# Template register map
Vendor: VendorName Co.Ltd; Series: SeriesName; File version: 1.2
CPU: CM7 r0p1, little endian, MPU, FPU, 4 interrupt priority bits
Registers are 32-bit, read-write, no defined reset value unless marked. A register's access mark holds for its fields unless they carry their own. Offsets are from the block's base; [hi:lo] are bit positions; {n}, {i} and the like mark numbered series.

## SMPU — System Memory Protection Unit
Base 0x400B3000
{0x0+4i} SEDMA1[{i}] (i=0..7) — Grouping of EDMA1 Start Addr
  [31:5] SEDMA1 — SMPU SEDMA1[26:0] bit: protection start address set of EDMA1 region n corrsponding MPU
{0x80+4i} SEDMA2[{i}] (i=0..7) — Grouping of EDMA2 Start Addr
  [31:5] SEDMA2 — SMPU SEDMA2[26:0] bit: protection start address set of EDMA2 region n corrsponding MPU
{0x100+4i} EEDMA1[{i}] (i=0..7) — Grouping of EDMA1 End Addr
  [31:5] EEDMA1 — SMPU EEDMA1[26:0] bit: protection end address set of EDMA1 region n corrsponding MPU
{0x180+4i} EEDMA2[{i}] (i=0..7) — Grouping of EDMA2 End Addr
  [31:5] EEDMA2 — SMPU EEDMA2[26:0] bit: protection end address set of EDMA2 region n corrsponding MPU
{0x200+4i} SAES[{i}] (i=0..3) — Grouping of AES-HASH Start Addr
  [31:5] SAES — SMPU SAES[26:0] bit: protection start address set of HASH-AES region n corrsponding MPU
{0x210+4i} SEMATH[{i}] (i=0..3) — Grouping of EMATH Start Addr
  [31:5] SEMATH — SMPU SEMATH[26:0] bit: protection start address set of EMATH region n corrsponding MPU
{0x220+4i} EAES[{i}] (i=0..3) — Grouping of AES-HASH End Addr
  [31:5] EAES — SMPU EAES[26:0] bit: protection end address set of HASH-AES region n corrsponding MPU
{0x230+4i} EEMATH[{i}] (i=0..3) — Grouping of EMATH End Addr
  [31:5] EEMATH — SMPU EEMATH[26:0] bit: protection end address set of EMATH region n corrsponding MPU
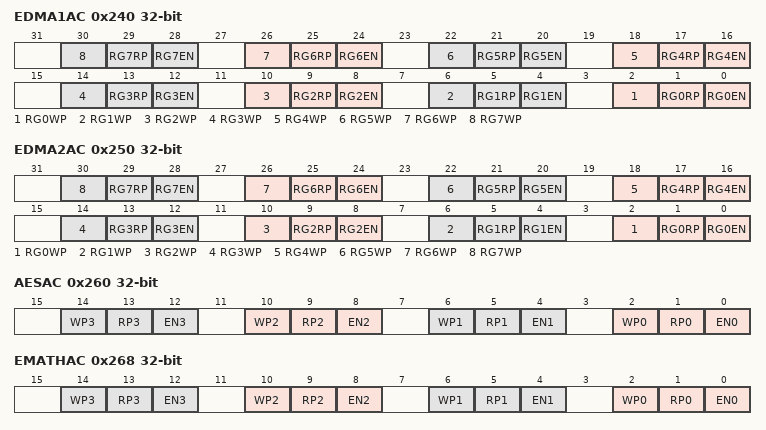
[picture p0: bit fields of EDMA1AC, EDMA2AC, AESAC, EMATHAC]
0x240 EDMA1AC — SMPU EDMA1 read-write access permission control register
  [4n+2] RG{n}WP (n=0..7) — SMPU RG{n}WP bit: region {n} EDMA1 MPU write protection
  [4n+1] RG{n}RP (n=0..7) — SMPU RG{n}RP bit: region {n} EDMA1 MPU read protection
  [4n] RG{n}EN (n=0..7) — SMPU RG{n}EN bit: region {n} EDMA1 MPU protection enable
0x250 EDMA2AC — SMPU EDMA2 read-write access permission control register
  [4n+2] RG{n}WP (n=0..7) — SMPU RG{n}WP bit: region {n} EDMA2 MPU write protection
  [4n+1] RG{n}RP (n=0..7) — SMPU RG{n}RP bit: region {n} EDMA2 MPU read protection
  [4n] RG{n}EN (n=0..7) — SMPU RG{n}EN bit: region {n} EDMA2 MPU protection enable
0x260 AESAC — SMPU HASH-AES read-write access permission control register
  [4n+2] WP{n} (n=0..3) — SMPU WP{n} bit: region {n} HASH-AES MPU write protection
  [4n+1] RP{n} (n=0..3) — SMPU RP{n} bit: region {n} HASH-AES MPU read protection
  [4n] EN{n} (n=0..3) — SMPU EN{n} bit: region {n} HASH-AES MPU protection enable
0x268 EMATHAC — SMPU EMATH read-write access permission control register
  [4n+2] WP{n} (n=0..3) — SMPU WP{n} bit: region {n} EMATH MPU write protection
  [4n+1] RP{n} (n=0..3) — SMPU RP{n} bit: region {n} EMATH MPU read protection
  [4n] EN{n} (n=0..3) — SMPU EN{n} bit: region {n} EMATH MPU protection enable
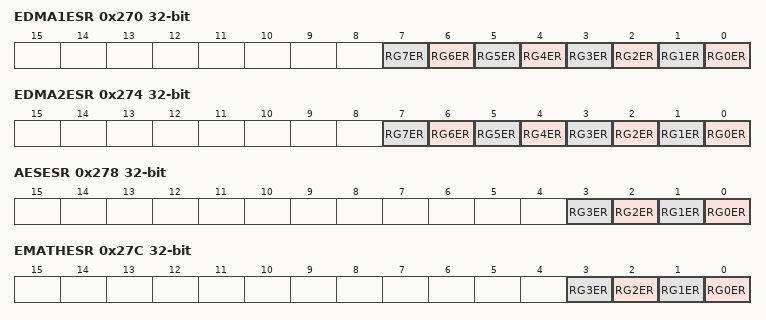
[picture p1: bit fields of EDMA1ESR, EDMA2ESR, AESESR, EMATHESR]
0x270 EDMA1ESR ro — SMPU EDMA1 MPU error status register
  [n] RG{n}ER (n=0..7) — SMPU RG{n}ER bit: EDMA1 region {n} whether have MPU access vilation error
0x274 EDMA2ESR ro — SMPU EDMA2 MPU error status register
  [n] RG{n}ER (n=0..7) — SMPU RG{n}ER bit: EDMA2 region {n} whether have MPU access vilation error
0x278 AESESR ro — SMPU HASH-AES MPU error status register
  [n] RG{n}ER (n=0..3) — SMPU RG{n}ER bit: HASH-AES region {n} whether have MPU access vilation error
0x27C EMATHESR ro — SMPU EMATH MPU error status register
  [n] RG{n}ER (n=0..3) — SMPU RG{n}ER bit: EMATH region {n} whether have MPU access vilation error
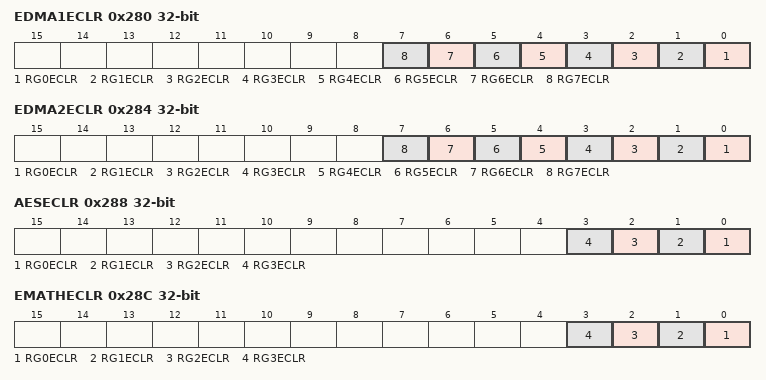
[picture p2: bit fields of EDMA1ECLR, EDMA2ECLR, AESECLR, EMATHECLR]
0x280 EDMA1ECLR — SMPU EDMA1 MPU error status clear register
  [n] RG{n}ECLR (n=0..7) — SMPU RG{n}ECLR bit: region {n} EDMA1 MPU error status clear
0x284 EDMA2ECLR — SMPU EDMA2 MPU error status clear register
  [n] RG{n}ECLR (n=0..7) — SMPU RG{n}ECLR bit: region {n} EDMA2 MPU error status clear
0x288 AESECLR — SMPU HASH-AES MPU error status clear register
  [n] RG{n}ECLR (n=0..3) — SMPU RG{n}ECLR bit: region {n} HASH-AES MPU error status clear
0x28C EMATHECLR — SMPU EMATH MPU error status clear register
  [n] RG{n}ECLR (n=0..3) — SMPU RG{n}ECLR bit: region {n} EMATH MPU error status clear
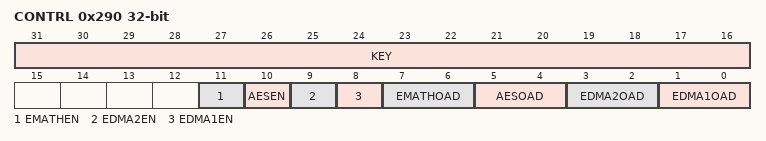
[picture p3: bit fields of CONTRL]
0x290 CONTRL — SMPU entirety control register
  [31:16] KEY wo — SMPU KEY[15:0] bit: only when 0x5A69 is written can this register be written
  [11] EMATHEN — SMPU EMATHEN bit: bus master MPU of EMATCH monitoring function enable
  [10] AESEN — SMPU AESEN bit: bus master MPU of HASH-AES monitoring function enable
  [9] EDMA2EN — SMPU EDMA2EN bit: bus master MPU of EDMA2 monitoring function enable
  [8] EDMA1EN — SMPU EDMA1EN bit: bus master MPU of EDMA1 monitoring function enable
  [7:6] EMATHOAD — SMPU EMATHOAD[1:0] bit: action mode select after MPU violation checkout of EMATH
  [5:4] AESOAD — SMPU AESOAD[1:0] bit: action mode select after MPU violation checkout of HASH-AES
  [3:2] EDMA2OAD — SMPU EDMA2OAD[1:0] bit: action mode select after MPU violation checkout of EDMA2
  [1:0] EDMA1OAD — SMPU EDMA1OAD[1:0] bit: action mode select after MPU violation checkout of EDMA1
